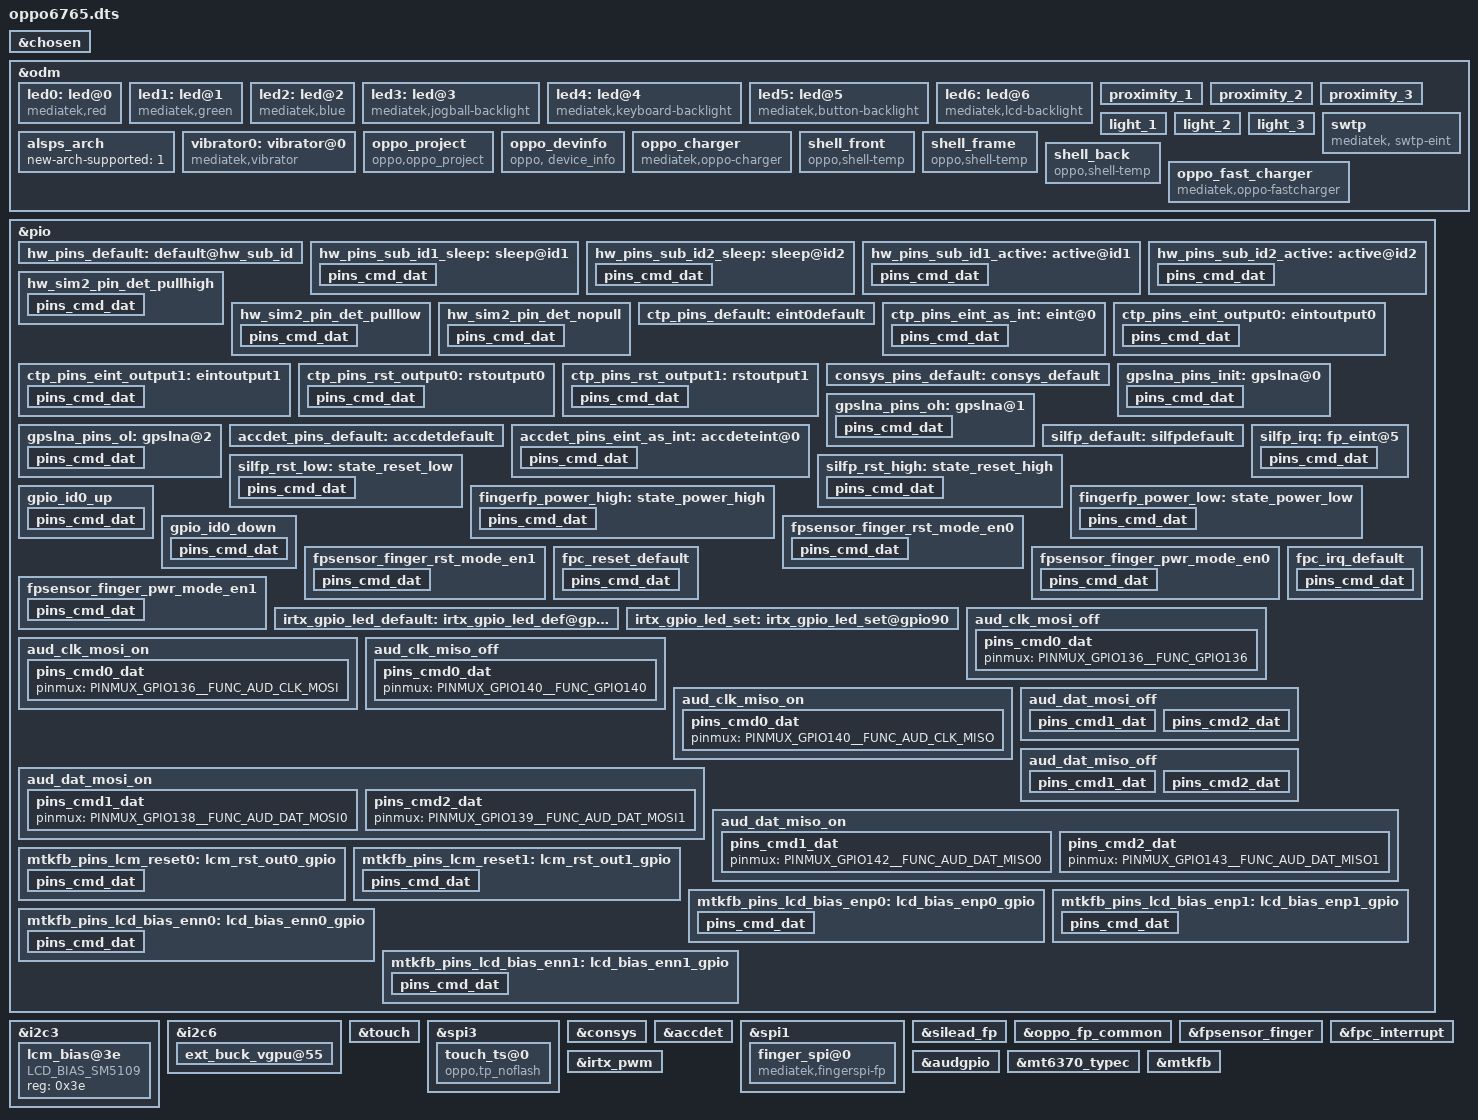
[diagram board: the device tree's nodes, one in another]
/*
 * Copyright (C) 2019 MediaTek Inc.
 *
 * This program is free software; you can redistribute it and/or modify
 * it under the terms of the GNU General Public License version 2 as
 * published by the Free Software Foundation.
 *
 * This program is distributed in the hope that it will be useful,
 * but WITHOUT ANY WARRANTY; without even the implied warranty of
 * MERCHANTABILITY or FITNESS FOR A PARTICULAR PURPOSE.
 * See http://www.gnu.org/licenses/gpl-2.0.html for more details.
 */

#include <dt-bindings/interrupt-controller/arm-gic.h>
#include <dt-bindings/interrupt-controller/irq.h>
#include <dt-bindings/pinctrl/mt6765-pinfunc.h>
#include <dt-bindings/clock/mt6765-clk.h>

/dts-v1/;
/plugin/;

/* chosen */
&chosen {

	/* fpga may has no lk, we need to specify display info here */
	/* fb buffer is reserved using this dts by memory node above */
	atag,videolfb-fb_base_h = <0x0>;
	atag,videolfb-fb_base_l = <0x5e605000>;
	atag,videolfb-islcmfound = <1>;
	/* because no lk, so lcm is not inited */
	atag,videolfb-islcm_inited = <0>;
	atag,videolfb-fps= <6000>;
	atag,videolfb-vramSize= <0x017bb000>;
	atag,videolfb-lcmname= "nt35695B_fhd_dsi_cmd_auo_rt5081_drv";
};

&odm {
	led0:led@0 {
		compatible = "mediatek,red";
		led_mode = <0>;
		data = <1>;
		pwm_config = <0 0 0 0 0>;
	};
	led1:led@1 {
		compatible = "mediatek,green";
		led_mode = <0>;
		data = <1>;
		pwm_config = <0 0 0 0 0>;
	};
	led2:led@2 {
		compatible = "mediatek,blue";
		led_mode = <0>;
		data = <1>;
		pwm_config = <0 0 0 0 0>;
	};
	led3:led@3 {
		compatible = "mediatek,jogball-backlight";
		led_mode = <0>;
		data = <1>;
		pwm_config = <0 0 0 0 0>;
	};
	led4:led@4 {
		compatible = "mediatek,keyboard-backlight";
		led_mode = <0>;
		data = <1>;
		pwm_config = <0 0 0 0 0>;
	};
	led5:led@5 {
		compatible = "mediatek,button-backlight";
		led_mode = <0>;
		data = <1>;
		pwm_config = <0 0 0 0 0>;
	};
	led6:led@6 {
		compatible = "mediatek,lcd-backlight";
		led_mode = <4>;
		data = <1>;
		pwm_config = <0 3 0 0 0>;
	};
	//#ifdef VENDOR_EDIT
	/* sensor start */
	/*Fei.Mo@PSW.BSP.Sensor, 2017/12/18, Add for sensor device tree */
	/*
	enum {
		TMD2725,
		APSD9922,
		STK3335,
		STK3331,
		STK2232,
		TCS3701,
		STK32600,
	};
	*/
	proximity_1: proximity_1 {
		status = "okay";
		sensor_name = <6>;//STK32600
		i2c_num = <0>;
		i2c_addr = <72>;
		direction = <4>;
		eint_num = <11>;
		low_step = <300>;
		high_step = <400>;
		low_limit = <650>;
		high_limit = <1050>;
		dirty_low_step = <300>;
		dirty_high_step = <400>;
		ps_dirty_limit = <1800>;
		ps_ir_limit = <2000>;
		ps_adjust_min = <0>;
		ps_adjust_max = <1850>;
		sampling_count = <5>;
		step_max = <400>;
		step_min = <100>;
		step_div = <2000>;
		anti_shake_delta = <70>;
		dynamic_cali_max = <2000>;
		raw2offset_radio = <1000>;
		offset_max = <60000>;
		offset_range_min = <0>;
		offset_range_max = <65534>;
		force_cali_limit = <2000>;
		cali_jitter_limit = <20>;
		cal_offset_margin = <3000>;
	};
	proximity_2: proximity_2 {
		status = "okay";
		sensor_name = <5>;//TCS3701
		i2c_num = <0>;
		i2c_addr = <57>;
		direction = <4>;
		eint_num = <11>;
		low_step = <300>;
		high_step = <400>;
		low_limit = <400>;
		high_limit = <600>;
		dirty_low_step = <180>;
		dirty_high_step = <250>;
		ps_dirty_limit = <1023>;
		ps_ir_limit = <500>;
		ps_adjust_min = <0>;
		ps_adjust_max = <600>;
		sampling_count = <5>;
		step_max = <400>;
		step_min = <110>;
		step_div = <1500>;
		anti_shake_delta = <80>;
		dynamic_cali_max = <1024>;
		raw2offset_radio = <20800>;
		offset_max = <250>;
		offset_range_min = <255>;
		offset_range_max = <255>;
		force_cali_limit = <2000>;
		cali_jitter_limit = <30>;
		cal_offset_margin = <120>;
	};
	proximity_3: proximity_3 {
		status = "okay";
		sensor_name = <3>;//STK3331
		i2c_num = <0>;
		i2c_addr = <71>;
		direction = <4>;
		eint_num = <10>;
		low_step = <300>;
		high_step = <400>;
		low_limit = <650>;
		high_limit = <1050>;
		dirty_low_step = <200>;
		dirty_high_step = <300>;
		ps_dirty_limit = <1800>;
		ps_ir_limit = <2000>;
		ps_adjust_min = <0>;
		ps_adjust_max = <1850>;
		sampling_count = <5>;
		step_max = <400>;
		step_min = <100>;
		step_div = <1500>;
		anti_shake_delta = <80>;
		dynamic_cali_max = <5000>;
		raw2offset_radio = <1000>;
		offset_max = <60000>;
		offset_range_min = <0>;
		offset_range_max = <65534>;
		force_cali_limit = <2000>;
		cali_jitter_limit = <20>;
		cal_offset_margin = <3000>;
	};
	light_1: light_1 {
		status = "okay";
		sensor_name = <6>;//STK32600
		i2c_num = <0>;
		i2c_addr = <72>;
		direction = <4>;
		eint_num = <11>;
	};
	light_2: light_2 {
		status = "okay";
		sensor_name = <5>;//TCS3701
		i2c_num = <0>;
		i2c_addr = <57>;
		direction = <4>;
		eint_num = <11>;
	};
	light_3: light_3 {
		status = "okay";
		sensor_name = <3>;//STK3331
		i2c_num = <0>;
		i2c_addr = <71>;
		direction = <4>;
		eint_num = <10>;
	};
	alsps_arch: alsps_arch {
		status = "okay";
		new-arch-supported = <1>;
	};
	//#endif
	vibrator0:vibrator@0 {
		compatible = "mediatek,vibrator";
		/*
		vib_timer = <25>;
		vib_limit = <9>;
		vib_vol= <9>;
		*/
/* Tiancheng.Peng@ODM_WT.BSP.POWER 2020/04/09,add vibrator vol to 3V*/
		vib_timer = <30>;
		vib_limit = <0>;
		vib_vol= <11>;
	};
//#ifdef ODM_WT_EDIT
/*Xin.Kou@ODM_WT.NW.RF.swtp, 2020/04/08, Add for swtp, RF cable detect */
	swtp:swtp {
		compatible = "mediatek, swtp-eint";
	};
//#endif /*ODM_WT_EDIT*/
//#ifdef ODM_WT_EDIT
/* Haibo.Dong@ODM_WT.BSP.Storage.Emmc 2020/03/28,add oppo project framework*/
	oppo_project:oppo_project {
		compatible = "oppo,oppo_project";
	};
/* Haibo.Dong@ODM_WT.BSP.Storage.Emmc 2020/04/02,add oppo devinfo framework*/
	oppo_devinfo:oppo_devinfo {
		compatible = "oppo, device_info";
	};
//#endif /*ODM_WT_EDIT*/

//#ifdef ODM_WT_EDIT
/*Sidong.Zhao@ODM_WT.BSP.CHG 2019/11/4,add oppo charge framework*/
	oppo_charger: oppo_charger {
		compatible = "mediatek,oppo-charger";
		//pinctrl-names = "default", "charger_gpio_as_output_low", "charger_gpio_as_output_high", "ship_sleep", "ship_active", "shortc_active";
		//pinctrl-0 = <&charger_pins_default>;
		//pinctrl-1 = <&charger_pins_eint_output0>;
		//pinctrl-2 = <&charger_pins_eint_output1>;
		//pinctrl-3 = <&ship_sleep_gpio>;
		//pinctrl-4 = <&ship_active_gpio>;
		//pinctrl-5 = <&shortc_active_gpio>;

		//for oppo chg framework:
		qcom,input_current_charger_ma = <2000>;
		qcom,input_current_cdp_ma = <1500>;
		qcom,input_current_usb_ma = <500>;
		qcom,input_current_led_ma = <1200>;
		qcom,input_current_led_ma_forcmcc = <500>;
		qcom,input_current_camera_ma = <1200>;
		qcom,input_current_calling_ma = <1200>;
		
		qcom,input_current_led_ma_high = <1200>;
		qcom,input_current_led_ma_warm = <1500>;
		qcom,input_current_led_ma_normal = <2000>;

		qcom,led_high_bat_decidegc = <370>;
		qcom,led_warm_bat_decidegc = <350>;

		qcom,iterm_disabled = <0>;
		qcom,iterm_ma = <205>;
		qcom,recharge-mv = <100>;

		qcom,batt_capacity_mah = <4230>; /*typical capacity*/
		//qcom,batt_capacity_mah = <3900>; /*rated capacity*/

		qcom,removed_bat_decidegc = <190>;  /* < -19C */

		qcom,cold_bat_decidegc = <20>;  /* -2C ~ 0C */
		qcom,temp_cold_vfloat_mv = <3980>;
		qcom,temp_cold_fastchg_current_ma = <350>;

		qcom,little_cold_bat_decidegc = <0>;	/* 0C ~ 5C */
		qcom,temp_little_cold_vfloat_mv = <4385>;
		qcom,temp_little_cold_fastchg_current_ma_high = <550>;
		qcom,temp_little_cold_fastchg_current_ma_low = <550>;
		qcom,temp_little_cold_fastchg_current_ma = <550>;
		monet,temp_little_cold_usbchg_current_ma_high = <650>;
		monet,temp_little_cold_usbchg_current_ma_low = <650>;
		monet,temp_little_cold_usbchg_current_ma = <650>;

		qcom,cool_bat_decidegc = <50>;	/* 5C ~ 12C */
		qcom,temp_cool_vfloat_mv = <4385>;
		qcom,temp_cool_fastchg_current_ma_high = <1150>;
		qcom,temp_cool_fastchg_current_ma_low = <550>;
		monet,temp_cool_usbchg_current_ma_high = <650>;
		monet,temp_cool_usbchg_current_ma_low = <550>;

		qcom,little_cool_bat_decidegc = <120>;	/* 12C ~ 16C */
		qcom,temp_little_cool_vfloat_mv = <4385>;
		qcom,temp_little_cool_fastchg_current_ma = <1700>;
		monet,temp_little_cool_usbchg_current_ma = <550>;

		qcom,normal_bat_decidegc = <160>;	/* 16C ~ 45C */
		qcom,temp_normal_fastchg_current_ma = <2200>;
		monet,temp_normal_usbchg_current_ma = <550>;
		qcom,temp_normal_vfloat_mv = <4385>;

		qcom,warm_bat_decidegc = <440>;		/* 44C ~ 53C */ /*8pin Bat Vooc project need add 3 degree C*/
		qcom,temp_warm_vfloat_mv = <4130>;
		qcom,temp_warm_fastchg_current_ma = <1150>;
		monet,temp_warm_usbchg_current_ma = <550>;
		qcom,temp_warm_fastchg_current_ma_led_on = <500>;

		qcom,hot_bat_decidegc = <530>;  /* > 53C */

		qcom,non_standard_vfloat_mv = <3980>;
		qcom,non_standard_fastchg_current_ma = <512>;

		qcom,short_c_bat_cv_mv = <4330>;
		qcom,short_c_bat_vfloat_mv = <3800>;
		qcom,short_c_bat_fastchg_current_ma = <512>;
		qcom,short_c_bat_vfloat_sw_limit = <3750>;

		qcom,cold_vfloat_sw_limit = <3930>;
		qcom,little_cold_vfloat_sw_limit = <4335>;
		qcom,cool_vfloat_sw_limit = <4335>;
		qcom,little_cool_vfloat_sw_limit = <4335>;
		qcom,normal_vfloat_sw_limit = <4335>;
		qcom,warm_vfloat_sw_limit = <4080>;
		qcom,non_standard_vfloat_sw_limit = <3930>;

		qcom,max_chg_time_sec = <36000>;
		qcom,charger_hv_thr = <5800>;
		qcom,charger_recv_thr = <5800>;
		qcom,charger_lv_thr = <3400>;
		qcom,vbatt_full_thr = <4400>;
		qcom,vbatt_hv_thr = <4500>;

		qcom,vfloat_step_mv = <10>;
		qcom,non_standard_vfloat_over_sw_limit = <4000>;
		qcom,cold_vfloat_over_sw_limit = <4000>;
		qcom,little_cold_vfloat_over_sw_limit = <4400>;
		qcom,cool_vfloat_over_sw_limit = <4400>;
		qcom,little_cool_vfloat_over_sw_limit = <4400>;
		qcom,normal_vfloat_over_sw_limit = <4400>;
		qcom,warm_vfloat_over_sw_limit = <4150>;

		qcom,vbatt_power_off = <3300>;
		qcom,vbatt_soc_1 = <3410>;
		qcom,vooc_project = <0>;
		qcom,vbatt_num = <1>;

		qcom,normal_vterm_hw_inc = <150>;
		qcom,non_normal_vterm_hw_inc = <10>;

		qcom,ff1_normal_fastchg_ma = <1088>;
		qcom,ffc2_normal_fastchg_ma = <780>;/*16C~35c*/
		qcom,ffc2_temp_warm_decidegc = <350>;
		qcom,ffc2_warm_fastchg_ma = <840>;/*35C~40c*/
		qcom,ffc2_temp_high_decidegc = <400>;
		qcom,ffc2_temp_low_decidegc = <120>;
		qcom,ff1_exit_step_ma = <488>;
		qcom,ff1_warm_exit_step_ma = <418>;
		qcom,ffc2_exit_step_ma = <180>;
		qcom,ffc2_warm_exit_step_ma = <170>;

		qcom,ffc_normal_vfloat_sw_limit = <4430>;
		qcom,ffc_temp_normal_vfloat_mv = <4500>;
		qcom,ffc_normal_vfloat_over_sw_limit = <4500>;

		qcom,default_iterm_ma = <205>;
		qcom,default_temp_normal_fastchg_current_ma = <2200>;
		qcom,default_normal_vfloat_sw_limit = <4335>;
		qcom,default_temp_normal_vfloat_mv = <4385>;
		qcom,default_normal_vfloat_over_sw_limit = <4400>;

		//for 2nd chip:
		qcom,iterm_ma_2nd = <300>;
		qcom,recharge-mv_2nd = <121>;

		qcom,temp_little_cold_vfloat_mv_2nd = <4391>;	/* 0C ~ 5C */
		qcom,temp_cool_vfloat_mv_2nd = <4391>;	/* 5C ~ 12C */
		qcom,temp_little_cool_vfloat_mv_2nd = <4391>;	/* 12C ~ 16C */
		qcom,temp_normal_vfloat_mv_2nd = <4391>;	/* 16C ~ 45C */

		qcom,little_cold_vfloat_over_sw_limit_2nd = <4395>;
		qcom,cool_vfloat_over_sw_limit_2nd = <4395>;
		qcom,little_cool_vfloat_over_sw_limit_2nd = <4395>;
		qcom,normal_vfloat_over_sw_limit_2nd = <4395>;

		qcom,default_iterm_ma_2nd = <300>;
		qcom,default_temp_normal_vfloat_mv_2nd = <4391>;
		qcom,default_normal_vfloat_over_sw_limit_2nd = <4395>;

		//for control:
		//qcom,suspend_after_full;
		qcom,check_batt_full_by_sw;
		//qcom,external_gauge;
		qcom,chg_ctrl_by_calling;
		qcom,chg_ctrl_by_lcd;
		qcom,chg_ctrl_by_camera;
		qcom,sw_vfloat_over_protect_enable;
		//qcom,ffc_support;

		//GPIO config:
		//qcom,chargerid_switch-gpio = <&pio 97 0x00>;
		//qcom,ship-gpio = <&pio 155 0x00>;
		//qcom,shortc-gpio = <&pio 77 0x00>;
	};

//#ifdef VENDOR_EDIT
//pengjingang@PSW.SH 2020/04/09  add for thermal shell temp
	shell_front {
		compatible = "oppo,shell-temp";
	};

	shell_frame {
		compatible = "oppo,shell-temp";
	};

	shell_back {
		compatible = "oppo,shell-temp";
	};
//#endif

oppo_fast_charger: oppo_fast_charger {
		compatible = "mediatek,oppo-fastcharger";
		//pinctrl-names = "default", "charger_gpio_as_output_low", "charger_gpio_as_output_high", "ship_sleep", "ship_active", "shortc_active";
		//pinctrl-0 = <&charger_pins_default>;
		//pinctrl-1 = <&charger_pins_eint_output0>;
		//pinctrl-2 = <&charger_pins_eint_output1>;
		//pinctrl-3 = <&ship_sleep_gpio>;
		//pinctrl-4 = <&ship_active_gpio>;
		//pinctrl-5 = <&shortc_active_gpio>;

		//for oppo chg framework:
		qcom,input_current_charger_ma = <2000>;
		qcom,input_current_cdp_ma = <1500>;
		qcom,input_current_usb_ma = <500>;
		qcom,input_current_led_ma = <1200>;
		qcom,input_current_led_ma_forcmcc = <500>;
		qcom,input_current_camera_ma = <1200>;
		qcom,input_current_calling_ma = <1200>;

		qcom,input_current_led_ma_high = <1000>;
		qcom,input_current_led_ma_warm = <1500>;
		qcom,input_current_led_ma_normal = <2000>;

		qcom,led_high_bat_decidegc = <370>;
		qcom,led_warm_bat_decidegc = <340>;

		qcom,iterm_disabled = <0>;
		qcom,iterm_ma = <265>;
		qcom,recharge-mv = <115>;

		qcom,batt_capacity_mah = <5000>; /*typical capacity*/
		//qcom,batt_capacity_mah = <3900>; /*rated capacity*/

		qcom,removed_bat_decidegc = <190>;  /* < -19C */

		qcom,cold_bat_decidegc = <20>;  /* -2C ~ 0C */
		qcom,temp_cold_vfloat_mv = <3980>;
		qcom,temp_cold_fastchg_current_ma = <350>;

		qcom,little_cold_bat_decidegc = <0>;	/* 0C ~ 5C */
		qcom,temp_little_cold_vfloat_mv = <4435>;
		qcom,temp_little_cold_fastchg_current_ma_high = <650>;
		qcom,temp_little_cold_fastchg_current_ma_low = <650>;
		qcom,temp_little_cold_fastchg_current_ma = <650>;
		monet,temp_little_cold_usbchg_current_ma_high = <650>;
		monet,temp_little_cold_usbchg_current_ma_low = <650>;
		monet,temp_little_cold_usbchg_current_ma = <650>;

		qcom,cool_bat_decidegc = <50>;	/* 5C ~ 12C */
		qcom,temp_cool_vfloat_mv = <4435>;
		qcom,temp_cool_fastchg_current_ma_high = <1350>;
		qcom,temp_cool_fastchg_current_ma_low = <650>;
		monet,temp_cool_usbchg_current_ma_high = <650>;
		monet,temp_cool_usbchg_current_ma_low = <550>;

		qcom,little_cool_bat_decidegc = <120>;	/* 12C ~ 16C */
		qcom,temp_little_cool_vfloat_mv = <4435>;
		qcom,temp_little_cool_fastchg_current_ma = <2050>;
		monet,temp_little_cool_usbchg_current_ma = <550>;

		qcom,normal_bat_decidegc = <160>;	/* 16C ~ 45C */
		qcom,temp_normal_fastchg_current_ma = <2200>;
		monet,temp_normal_usbchg_current_ma = <550>;
		qcom,temp_normal_vfloat_mv = <4435>;

		qcom,warm_bat_decidegc = <450>;		/* 45C ~ 53C */ /*8pin Bat Vooc project need add 3 degree C*/
		qcom,temp_warm_vfloat_mv = <4130>;
		qcom,temp_warm_fastchg_current_ma = <1350>;
		monet,temp_warm_usbchg_current_ma = <550>;
		qcom,temp_warm_fastchg_current_ma_led_on = <500>;

		qcom,hot_bat_decidegc = <530>;  /* > 53C */

		qcom,non_standard_vfloat_mv = <3980>;
		qcom,non_standard_fastchg_current_ma = <512>;

		qcom,short_c_bat_cv_mv = <4330>;
		qcom,short_c_bat_vfloat_mv = <3800>;
		qcom,short_c_bat_fastchg_current_ma = <512>;
		qcom,short_c_bat_vfloat_sw_limit = <3750>;

		qcom,cold_vfloat_sw_limit = <3930>;
		qcom,little_cold_vfloat_sw_limit = <4380>;
		qcom,cool_vfloat_sw_limit = <4380>;
		qcom,little_cool_vfloat_sw_limit = <4380>;
		qcom,normal_vfloat_sw_limit = <4380>;
		qcom,warm_vfloat_sw_limit = <4080>;
		qcom,non_standard_vfloat_sw_limit = <3930>;

		qcom,max_chg_time_sec = <36000>;
		qcom,charger_hv_thr = <9800>;
		qcom,charger_recv_thr = <9800>;
		qcom,charger_lv_thr = <3400>;
		qcom,vbatt_full_thr = <4400>;
		qcom,vbatt_hv_thr = <4550>;

		qcom,vfloat_step_mv = <10>;
		qcom,non_standard_vfloat_over_sw_limit = <4000>;
		qcom,cold_vfloat_over_sw_limit = <4000>;
		qcom,little_cold_vfloat_over_sw_limit = <4450>;
		qcom,cool_vfloat_over_sw_limit = <4450>;
		qcom,little_cool_vfloat_over_sw_limit = <4450>;
		qcom,normal_vfloat_over_sw_limit = <4450>;
		qcom,warm_vfloat_over_sw_limit = <4150>;

		qcom,vbatt_power_off = <3300>;
		qcom,vbatt_soc_1 = <3410>;
		qcom,vooc_project = <0>;
		qcom,vbatt_num = <1>;

		qcom,normal_vterm_hw_inc = <150>;
		qcom,non_normal_vterm_hw_inc = <10>;

		qcom,ff1_normal_fastchg_ma = <1088>;
		qcom,ffc2_normal_fastchg_ma = <780>;/*16C~35c*/
		qcom,ffc2_temp_warm_decidegc = <350>;
		qcom,ffc2_warm_fastchg_ma = <840>;/*35C~40c*/
		qcom,ffc2_temp_high_decidegc = <400>;
		qcom,ffc2_temp_low_decidegc = <120>;
		qcom,ff1_exit_step_ma = <488>;
		qcom,ff1_warm_exit_step_ma = <418>;
		qcom,ffc2_exit_step_ma = <180>;
		qcom,ffc2_warm_exit_step_ma = <170>;

		qcom,ffc_normal_vfloat_sw_limit = <4430>;
		qcom,ffc_temp_normal_vfloat_mv = <4500>;
		qcom,ffc_normal_vfloat_over_sw_limit = <4500>;

		qcom,default_iterm_ma = <265>;
		qcom,default_temp_normal_fastchg_current_ma = <2200>;
		qcom,default_normal_vfloat_sw_limit = <4380>;
		qcom,default_temp_normal_vfloat_mv = <4435>;
		qcom,default_normal_vfloat_over_sw_limit = <4450>;

		//for 2nd chip:
		qcom,iterm_ma_2nd = <300>;
		qcom,recharge-mv_2nd = <121>;

		qcom,temp_little_cold_vfloat_mv_2nd = <4391>;	/* 0C ~ 5C */
		qcom,temp_cool_vfloat_mv_2nd = <4391>;	/* 5C ~ 12C */
		qcom,temp_little_cool_vfloat_mv_2nd = <4391>;	/* 12C ~ 16C */
		qcom,temp_normal_vfloat_mv_2nd = <4391>;	/* 16C ~ 45C */

		qcom,little_cold_vfloat_over_sw_limit_2nd = <4395>;
		qcom,cool_vfloat_over_sw_limit_2nd = <4395>;
		qcom,little_cool_vfloat_over_sw_limit_2nd = <4395>;
		qcom,normal_vfloat_over_sw_limit_2nd = <4395>;

		qcom,default_iterm_ma_2nd = <300>;
		qcom,default_temp_normal_vfloat_mv_2nd = <4391>;
		qcom,default_normal_vfloat_over_sw_limit_2nd = <4395>;

		//for control:
		//qcom,suspend_after_full;
		qcom,check_batt_full_by_sw;
		//qcom,external_gauge;
		qcom,chg_ctrl_by_calling;
		qcom,chg_ctrl_by_lcd;
		qcom,chg_ctrl_by_camera;
		qcom,sw_vfloat_over_protect_enable;
		//qcom,ffc_support;

		//GPIO config:
		//qcom,chargerid_switch-gpio = <&pio 97 0x00>;
		//qcom,ship-gpio = <&pio 155 0x00>;
		//qcom,shortc-gpio = <&pio 77 0x00>;

		qcom,vbatt_pdqc_to_5v_thr = <4420>;
		status = "okay";
	};
//#endif /*ODM_WT_EDIT*/
};
//#ifdef ODM_WT_EDIT
/* Haibo.Dong@ODM_WT.BSP.Storage.Emmc 2020/04/04,add sub_id match*/
&oppo_devinfo {
	Hw,sub_hwid_1 = <&pio 160 0x00>;
	Hw,sub_hwid_2 = <&pio 9 0x00>;
	Hw,sim2_det = <&pio 176 0x00>;
	pinctrl-names = "default", "hw_sub_id_sleep", "hw_sub_id_active","sim2_det_pullhigh","sim2_det_pulllow","sim2_det_nopull";
	pinctrl-0 = <&hw_pins_default>;
	pinctrl-1 = <&hw_pins_sub_id1_sleep>;
	pinctrl-2 = <&hw_pins_sub_id1_active>;
	pinctrl-3 = <&hw_sim2_pin_det_pullhigh>;
	pinctrl-4 = <&hw_sim2_pin_det_pulllow>;
	pinctrl-5 = <&hw_sim2_pin_det_nopull>;
};

&pio {
	hw_pins_default:default@hw_sub_id {
	};

	hw_pins_sub_id1_sleep:sleep@id1 {
			pins_cmd_dat {
				pinmux = <PINMUX_GPIO160__FUNC_GPIO160>;
				slew-rate = <0>;
				bias-pull-down = <00>;
				input-enable;
			};
	};

	hw_pins_sub_id2_sleep:sleep@id2 {
			pins_cmd_dat {
				pinmux = <PINMUX_GPIO9__FUNC_GPIO9>;
				bias-pull-down = <00>;
				input-enable;
			};
	};

	hw_pins_sub_id1_active:active@id1 {
		pins_cmd_dat {
			pinmux = <PINMUX_GPIO160__FUNC_GPIO160>;
			slew-rate = <0>;
			bias-pull-up = <00>;
			input-enable;
		};
	};
	hw_pins_sub_id2_active:active@id2 {
		pins_cmd_dat {
			pinmux = <PINMUX_GPIO9__FUNC_GPIO9>;
			slew-rate = <0>;
			bias-pull-up = <00>;
			input-enable;
		};
	};
	hw_sim2_pin_det_pullhigh:hw_sim2_pin_det_pullhigh {
		pins_cmd_dat {
			pinmux = <PINMUX_GPIO176__FUNC_GPIO176>;
			slew-rate = <0>;
			input-enable;
			bias-pull-up = <00>;
		};
	};
	hw_sim2_pin_det_pulllow:hw_sim2_pin_det_pulllow {
		pins_cmd_dat {
			pinmux = <PINMUX_GPIO176__FUNC_GPIO176>;
			slew-rate = <0>;
			input-enable;
			bias-pull-down = <00>;
		};
	};
	hw_sim2_pin_det_nopull:hw_sim2_pin_det_nopull {
		pins_cmd_dat {
			pinmux = <PINMUX_GPIO176__FUNC_GPIO176>;
			slew-rate = <0>;
			input-enable;
			bias-disable;
		};
	};
};
//#endif /*ODM_WT_EDIT*/

&i2c3 {
		lcm_bias@3e{
               compatible = "LCD_BIAS_SM5109","LCD_BIAS_OCP2130";
               reg = <0x3e>;
               status = "okay";
	};
};

&i2c6 {
	ext_buck_vgpu@55 {
		regulator-name ="ext_buck_vgpu";
		regulator-min-microvolt = <300000>;
		regulator-max-microvolt = <1300000>;
		vsel_pin = <2>;
	};
};
/* TOUCH start */
&touch {
	tpd-resolution = <720 1600>;
	use-tpd-button = <0>;
	tpd-key-num = <3>;
	tpd-key-local= <139 172 158 0>;
	tpd-key-dim-local = <90 883 100 40 230
				 883 100 40 370 883 100 40 0 0 0 0>;
	tpd-max-touch-num = <5>;
	tpd-filter-enable = <0>;
	tpd-filter-pixel-density = <146>;
	tpd-filter-custom-prameters = <0 0 0 0 0 0 0 0 0 0 0 0>;
	tpd-filter-custom-speed = <0 0 0>;
	pinctrl-names = "default", "state_eint_as_int", "state_eint_output0",
		"state_eint_output1", "state_rst_output0", "state_rst_output1";
	pinctrl-0 = <&ctp_pins_default>;
	pinctrl-1 = <&ctp_pins_eint_as_int>;
	pinctrl-2 = <&ctp_pins_eint_output0>;
	pinctrl-3 = <&ctp_pins_eint_output1>;
	pinctrl-4 = <&ctp_pins_rst_output0>;
	pinctrl-5 = <&ctp_pins_rst_output1>;
	status = "okay";
};
&pio {
	ctp_pins_default: eint0default {
	};
	ctp_pins_eint_as_int: eint@0 {
		pins_cmd_dat {
			pinmux = <PINMUX_GPIO0__FUNC_GPIO0>;
			slew-rate = <0>;
			bias-disable;
		};
	};
	ctp_pins_eint_output0: eintoutput0 {
		pins_cmd_dat {
			pinmux = <PINMUX_GPIO0__FUNC_GPIO0>;
			slew-rate = <1>;
			output-low;
		};
	};
	ctp_pins_eint_output1: eintoutput1 {
		pins_cmd_dat {
			pinmux = <PINMUX_GPIO0__FUNC_GPIO0>;
			slew-rate = <1>;
			output-high;
		};
	};
	ctp_pins_rst_output0: rstoutput0 {
		pins_cmd_dat {
			pinmux = <PINMUX_GPIO174__FUNC_GPIO174>;
			slew-rate = <1>;
			output-low;
		};
	};
	ctp_pins_rst_output1: rstoutput1 {
		pins_cmd_dat {
			pinmux = <PINMUX_GPIO174__FUNC_GPIO174>;
			slew-rate = <1>;
			output-high;
		};
	};
};

//Binbo.song@ODM_WT.BSP.Touchscreen.Base,2020/06/30,tp bringup add for inx/hlt/txd touchscreen mould dts config.
&spi3 {
    #address-cells = <1>;
    #size-cells = <0>;

    touch_ts@0 {
        reg = <0>;
        compatible = "oppo,tp_noflash","himax,hxcommon","ilitek,ilitek-ts-spi","novatek,NVT-ts-spi","novatek,nf_nt36525b";
        spi-max-frequency = <9600000>;
        status = "okay";
		//chip_name = "NF_NT36525B";
		chip_name_ilitek = "NF_ILI9881H";
		chip_name_ilitek_9882n = "NF_ILI9882N";
		chip_name_himax = "NF_HX83102D";
		chip_name_novatek = "NF_NT36525B";

        /* touch spi config */
		reset-gpio = <&pio 174 0x00>;
		interrupt-parent = <&pio>;
		interrupts = <0 IRQ_TYPE_EDGE_FALLING 0 0>;
		irq-gpio = <&pio 0 0x2002>;

		novatek,reset-gpio = <&pio 174 0x00>;
		novatek,irq-gpio = <&pio 0 0x2002>;

		touchpanel,max-num-support = <10>;
		touchpanel,tx-rx-num = <18 32>;
		touchpanel,panel-coords = <720 1600>;
		touchpanel,display-coords = <720 1600>;
		touchpanel,touchmajor-limit = <0 54>;

		incell_screen;
		fw_edge_limit_support;
		black_gesture_support;
		charger_pump_support;
		headset_pump_support;
		esd_handle_support;
		//spurious_fingerprint_support;
		//lcd_trigger_fp_check;
		black_gesture_test_support;
		noflash_support;
		smart_gesture_support;
		pressure_report_support;
		fw_update_app_support;
		game_switch_support;
		drlimit_remove_support;
		lcd_trigger_load_tp_fw_support;
		freq_hop_simulate_support;
		suspend_gesture_cfg;
		//fw_update_in_probe_with_headfile;
    };
};
/* TOUCH end */

/* CONSYS GPIO standardization */
&pio {
	consys_pins_default: consys_default {
	};
	gpslna_pins_init: gpslna@0 {
		pins_cmd_dat {
			pinmux = <PINMUX_GPIO91__FUNC_GPIO91>;
			slew-rate = <0>;
			bias-disable;
			output-low;
		};
	};
	gpslna_pins_oh: gpslna@1 {
		pins_cmd_dat {
			pinmux = <PINMUX_GPIO91__FUNC_GPIO91>;
			slew-rate = <1>;
			output-high;
		};
	};
	gpslna_pins_ol: gpslna@2 {
		pins_cmd_dat {
			pinmux = <PINMUX_GPIO91__FUNC_GPIO91>;
			slew-rate = <1>;
			output-low;
		};
	};
};
&consys {
	pinctrl-names = "default", "gps_lna_state_init",
		"gps_lna_state_oh", "gps_lna_state_ol";
	pinctrl-0 = <&consys_pins_default>;
	pinctrl-1 = <&gpslna_pins_init>;
	pinctrl-2 = <&gpslna_pins_oh>;
	pinctrl-3 = <&gpslna_pins_ol>;
	status = "okay";
};
/* CONSYS end */

/* accdet start */
&accdet {
        /*#ifdef ODM_WT_EDIT*/
        /*Shouxing.Tang@ODM_WT.MM.Audiodriver.accdet, 2020/4/4, change hs mic bias1 2.7v for 206A1*/
	accdet-mic-vol = <7>;
        /*#endif*/
	headset-mode-setting = <0x500 0x500 1 0x1f0 0x800 0x800 0x20 0x44>;
	accdet-plugout-debounce = <1>;
	accdet-mic-mode = <1>;
	headset-eint-level-pol = <8>;
	headset-three-key-threshold = <0 55 130 400>;
	headset-three-key-threshold-CDD = <0 121 192 600>;
	headset-four-key-threshold = <0 58 121 192 400>;
	pinctrl-names = "default", "state_eint_as_int";
	pinctrl-0 = <&accdet_pins_default>;
	pinctrl-1 = <&accdet_pins_eint_as_int>;
	status = "okay";
};
&pio {
	accdet_pins_default: accdetdefault {
	};
	accdet_pins_eint_as_int: accdeteint@0 {
		pins_cmd_dat {
			pinmux = <PINMUX_GPIO9__FUNC_GPIO9>;
			slew-rate = <0>;
			bias-disable;
		};
	};
};
/* accdet end */

//#ifdef ODM_WT_EDIT
//#Zhaoliang.Shi@ODM_WT.BSP.Fingerprint.Basic, 2018/9/25, Add for fingerprint driver
/* FINGERPRINT start */
&spi1 {
	#address-cells = <1>;
	#size-cells = <0>;
	finger_spi@0 {
		compatible = "mediatek,fingerspi-fp";
		reg = <0>;
		spi-max-frequency = <8000000>;
		netlink-event = <30>;
                spi-id = <1>;
                spi-irq = <5>;
                spi-reg = <0x11015000>;
		status = "okay";
	};
};

&silead_fp {
        pinctrl-names = "default", "rst-low", "rst-high",
                        "irq-init", "power_high","power_low";
        pinctrl-0 = <&silfp_default>;
        pinctrl-1 = <&silfp_rst_low>;
        pinctrl-2 = <&silfp_rst_high>;
        pinctrl-3 = <&silfp_irq>;
        pinctrl-4 = <&fingerfp_power_high>;
        pinctrl-5 = <&fingerfp_power_low>;
        status = "okay";
};

&pio {
        silfp_default: silfpdefault {
        };
        silfp_rst_low: state_reset_low {
                pins_cmd_dat {
                        pinmux = <PINMUX_GPIO7__FUNC_GPIO7>;
                        slew-rate = <1>;
                        output-low;
                };
        };
        silfp_rst_high: state_reset_high {
                pins_cmd_dat {
                        pinmux = <PINMUX_GPIO7__FUNC_GPIO7>;
                        slew-rate = <1>;
                        output-high;
                };
        };
        silfp_irq: fp_eint@5 {
                pins_cmd_dat {
                        pinmux = <PINMUX_GPIO5__FUNC_GPIO5>;
                        slew-rate = <0>;
                        bias-disable;
                };
        };
        fingerfp_power_high: state_power_high {
                pins_cmd_dat {
                        pinmux = <PINMUX_GPIO20__FUNC_GPIO20>;
                        slew-rate = <1>;
                        output-high;
                };
        };

        fingerfp_power_low: state_power_low {
                pins_cmd_dat {
                        pinmux = <PINMUX_GPIO20__FUNC_GPIO20>;
                        slew-rate = <1>;
                        output-low;
                };
        };
};


&oppo_fp_common {
	oppo,fp-id0 = <&pio 166 0x00>;
	pinctrl-names = "gpio_id0_up","gpio_id0_down";
	pinctrl-0 = <&gpio_id0_up>;
	pinctrl-1 = <&gpio_id0_down>;
	status = "okay";
 };

&pio {
	gpio_id0_up: gpio_id0_up {
		pins_cmd_dat {
			pinmux = <PINMUX_GPIO166__FUNC_GPIO166>;
			slew-rate = <0>;
			bias-pull-up;
			input-enable;
		};
	};
	gpio_id0_down: gpio_id0_down {
		pins_cmd_dat {
			pinmux = <PINMUX_GPIO166__FUNC_GPIO166>;
			slew-rate = <0>;
			bias-pull-down;
			input-enable;
		};
	};
};

&fpsensor_finger {
	interrupt-parent = <&gic>;
	interrupts = <5 IRQ_TYPE_EDGE_RISING>;
	debounce = <2 0>;
	pinctrl-names = "fpsensor_finger_rst_low","fpsensor_finger_rst_high","fpsensor_finger_pwr_low","fpsensor_finger_pwr_high";
	pinctrl-0 = <&fpsensor_finger_rst_mode_en0>;
	pinctrl-1 = <&fpsensor_finger_rst_mode_en1>;
	pinctrl-2 = <&fpsensor_finger_pwr_mode_en0>;
	pinctrl-3 = <&fpsensor_finger_pwr_mode_en1>;
	status = "okay";
};

&pio {
	fpsensor_finger_rst_mode_en0: fpsensor_finger_rst_mode_en0 {
		pins_cmd_dat {
			pinmux = <PINMUX_GPIO7__FUNC_GPIO7>;
			slew-rate = <1>;
			output-low;
		};
	};
	fpsensor_finger_rst_mode_en1: fpsensor_finger_rst_mode_en1 {
		pins_cmd_dat {
			pinmux = <PINMUX_GPIO7__FUNC_GPIO7>;
			slew-rate = <1>;
			output-high;
		};
	};

	fpsensor_finger_pwr_mode_en0: fpsensor_finger_pwr_mode_en0 {
		pins_cmd_dat {
			pinmux = <PINMUX_GPIO20__FUNC_GPIO20>;
			slew-rate = <1>;
			output-low;
		};
	};
	fpsensor_finger_pwr_mode_en1: fpsensor_finger_pwr_mode_en1 {
		pins_cmd_dat {
			pinmux = <PINMUX_GPIO20__FUNC_GPIO20>;
			slew-rate = <1>;
			output-high;
		};
	};
};

&fpc_interrupt {
	fpc,irq-gpio    = <&pio 5 0x00>;
	fpc,reset-gpio  = <&pio 7 0x00>;
	fpc,vdd-en = <&pio 18 0x00>;
	//fpc,gpio_cs = <&pio 157 0x00>;
	pinctrl-names = "default"/*, "fpc_cs_func"/*;
	pinctrl-0 = <&fpc_reset_default>,<&fpc_irq_default>/*,<&fpc_pwr_default>*/;
	//pinctrl-1 = <&gpio_fpc_cs_func>;
	status = "okay";
};

&pio {
	fpc_reset_default: fpc_reset_default {
		pins_cmd_dat {
			pinmux = <PINMUX_GPIO7__FUNC_GPIO7>;
			slew-rate = <1>;
			output-low;
		};
	};
	fpc_irq_default: fpc_irq_default {
		pins_cmd_dat {
			pinmux = <PINMUX_GPIO5__FUNC_GPIO5>;
			slew-rate = <0>;
			bias-pull-up;
		};
	};

	//fpc_pwr_default: fpc_pwr_default {
	//	pins_cmd_dat {
	//		pinmux = <PINMUX_GPIO20__FUNC_GPIO20>;
	//		slew-rate = <1>;
    //        bias-disable;
	//		output-low;
	//	};
	//};
    //gpio_fpc_cs_func: gpio_fpc_cs_func {
    //            pins_cmd_dat {
    //                    pinmux = <PINMUX_GPIO157__FUNC_SPI1_A_CSB>;
    //                    drive-strength = <3>;
    //            };
    //    };
};

/* FINGERPRINT end */
//#endif /*ODM_WT_EDIT*/


/* IRTX GPIO end */
&irtx_pwm {
	pinctrl-names = "irtx_gpio_led_default", "irtx_gpio_led_set";
	pinctrl-0 = <&irtx_gpio_led_default>;
	pinctrl-1 = <&irtx_gpio_led_set>;
	status = "okay";
};
&pio {
	irtx_gpio_led_default:irtx_gpio_led_def@gpio90 {
	};

	irtx_gpio_led_set:irtx_gpio_led_set@gpio90 {
	};
};
/* IRTX GPIO Settings -End */

/* AUDIO GPIO standardization */
&audgpio {
	pinctrl-names = "aud_clk_mosi_off",
			"aud_clk_mosi_on",
			"aud_clk_miso_off",
			"aud_clk_miso_on",
			"aud_dat_mosi_off",
			"aud_dat_mosi_on",
			"aud_dat_miso_off",
			"aud_dat_miso_on";
	pinctrl-0 = <&aud_clk_mosi_off>;
	pinctrl-1 = <&aud_clk_mosi_on>;
	pinctrl-2 = <&aud_clk_miso_off>;
	pinctrl-3 = <&aud_clk_miso_on>;
	pinctrl-4 = <&aud_dat_mosi_off>;
	pinctrl-5 = <&aud_dat_mosi_on>;
	pinctrl-6 = <&aud_dat_miso_off>;
	pinctrl-7 = <&aud_dat_miso_on>;

	status = "okay";
};

&pio {
	aud_clk_mosi_off: aud_clk_mosi_off {
		pins_cmd0_dat {
			pinmux = <PINMUX_GPIO136__FUNC_GPIO136>;
		};
	};

	aud_clk_mosi_on: aud_clk_mosi_on {
		pins_cmd0_dat {
			pinmux = <PINMUX_GPIO136__FUNC_AUD_CLK_MOSI>;
		};
	};

	aud_clk_miso_off: aud_clk_miso_off {
		pins_cmd0_dat {
			pinmux = <PINMUX_GPIO140__FUNC_GPIO140>;
		};
	};

	aud_clk_miso_on: aud_clk_miso_on {
		pins_cmd0_dat {
			pinmux = <PINMUX_GPIO140__FUNC_AUD_CLK_MISO>;
		};
	};

	aud_dat_mosi_off: aud_dat_mosi_off {
		pins_cmd1_dat {
			pinmux = <PINMUX_GPIO138__FUNC_GPIO138>;
			input-enable;
			slew-rate = <0>;
			bias-disable;
		};
		pins_cmd2_dat {
			pinmux = <PINMUX_GPIO139__FUNC_GPIO139>;
			input-enable;
			slew-rate = <0>;
			bias-disable;
		};
	};

	aud_dat_mosi_on: aud_dat_mosi_on {
		pins_cmd1_dat {
			pinmux = <PINMUX_GPIO138__FUNC_AUD_DAT_MOSI0>;
		};
		pins_cmd2_dat {
			pinmux = <PINMUX_GPIO139__FUNC_AUD_DAT_MOSI1>;
		};
	};

	aud_dat_miso_off: aud_dat_miso_off {
		pins_cmd1_dat {
			pinmux = <PINMUX_GPIO142__FUNC_GPIO142>;
			input-enable;
			slew-rate = <0>;
			bias-disable;
		};
		pins_cmd2_dat {
			pinmux = <PINMUX_GPIO143__FUNC_GPIO143>;
			input-enable;
			slew-rate = <0>;
			bias-disable;
		};
	};

	aud_dat_miso_on: aud_dat_miso_on {
		pins_cmd1_dat {
			pinmux = <PINMUX_GPIO142__FUNC_AUD_DAT_MISO0>;
		};
		pins_cmd2_dat {
			pinmux = <PINMUX_GPIO143__FUNC_AUD_DAT_MISO1>;
		};
	};

	
};
/* AUDIO end */

&mt6370_typec {
	mt6370pd,intr_gpio_num = <41>; /* direct defined GPIO num */
	mt6370pd,intr_gpio = <&pio 41 0x0>;
};

//#ifdef ODM_WT_EDIT
#include "rt9471_single.dtsi"
#include "bq25910.dtsi"
#include "bq2589x.dtsi"
//#endif /*ODM_WT_EDIT*/
/* Wu.Weihong@ODM_WT.MM.Display.Lcd, 2020/3/23, LCD bringup */
/* DISPSYS GPIO standardization */
&mtkfb {
        pinctrl-names = "lcm_rst_out0_gpio", "lcm_rst_out1_gpio", "lcd_bias_enp0_gpio", "lcd_bias_enp1_gpio",
			"lcd_bias_enn0_gpio", "lcd_bias_enn1_gpio", "lcd_vddio18_en0_gpio", "lcd_vddio18_en1_gpio";

	pinctrl-0 = <&mtkfb_pins_lcm_reset0>;
	pinctrl-1 = <&mtkfb_pins_lcm_reset1>;
	pinctrl-2 = <&mtkfb_pins_lcd_bias_enp0>;
	pinctrl-3 = <&mtkfb_pins_lcd_bias_enp1>;
	pinctrl-4 = <&mtkfb_pins_lcd_bias_enn0>;
	pinctrl-5 = <&mtkfb_pins_lcd_bias_enn1>;
	//pinctrl-6 = <&mtkfb_pins_lcd_vddio18_en0>;
	//pinctrl-7 = <&mtkfb_pins_lcd_vddio18_en1>;
        status = "okay";
};

&pio {
	mtkfb_pins_lcm_reset0: lcm_rst_out0_gpio {
			pins_cmd_dat {
					pinmux = <PINMUX_GPIO45__FUNC_GPIO45>;
					slew-rate = <1>;
					output-low;
			};
	};
	mtkfb_pins_lcm_reset1: lcm_rst_out1_gpio {
			pins_cmd_dat {
					pinmux = <PINMUX_GPIO45__FUNC_GPIO45>;
					slew-rate = <1>;
					output-high;
			};
	};

	mtkfb_pins_lcd_bias_enp0: lcd_bias_enp0_gpio {
                pins_cmd_dat {
                        pinmux = <PINMUX_GPIO150__FUNC_GPIO150>;
                        slew-rate = <1>;
                        output-low;
                };
        };
	mtkfb_pins_lcd_bias_enp1: lcd_bias_enp1_gpio {
                pins_cmd_dat {
                        pinmux = <PINMUX_GPIO150__FUNC_GPIO150>;
                        slew-rate = <1>;
                        output-high;
                };
        };

	mtkfb_pins_lcd_bias_enn0: lcd_bias_enn0_gpio {
                pins_cmd_dat {
                        pinmux = <PINMUX_GPIO151__FUNC_GPIO151>;
                        slew-rate = <1>;
                        output-low;
                };
        };
	mtkfb_pins_lcd_bias_enn1: lcd_bias_enn1_gpio {
                pins_cmd_dat {
                        pinmux = <PINMUX_GPIO151__FUNC_GPIO151>;
                        slew-rate = <1>;
                        output-high;
                };
        };
};
/* Wu.Weihong@ODM_WT.MM.Display.Lcd, 2020/3/23, LCD bringup */
#include <oppo6765/cust.dtsi>
#include "cust_mt6765_camera.dtsi"
/*End of this file, DO NOT ADD ANYTHING HERE*/
